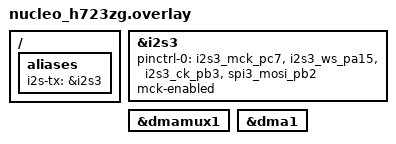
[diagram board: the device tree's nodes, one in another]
/*
 * Copyright (c) 2026 Mario Paja
 *
 * SPDX-License-Identifier: Apache-2.0
 */

/ {
	aliases {
		i2s-tx = &i2s3;
	};
};

/* Half-Duplex Master Transmit */
&i2s3 {
	pinctrl-0 = <&i2s3_mck_pc7 &i2s3_ws_pa15
		     &i2s3_ck_pb3 &spi3_mosi_pb2>;
	pinctrl-names = "default";
	mck-enabled;
	status = "okay";
};

&dmamux1 {
	status = "okay";
};

&dma1 {
	status = "okay";
};
